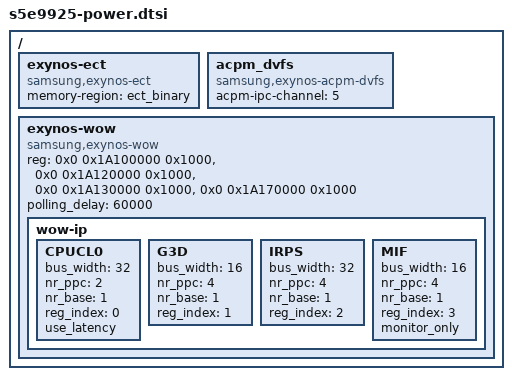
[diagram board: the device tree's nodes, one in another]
/*
 * SAMSUNG EXYNOS2100 SoC DVFS Manager device tree source
 *
 * Copyright (c) 2014 Samsung Electronics Co., Ltd.
 *		http://www.samsung.com
 *
 * SAMSUNG EXYNOS2100 SoC device nodes are listed in this file.
 * EXYNOS based board files can include this file and provide
 * values for board specfic bindings.
 *
 * This program is free software; you can redistribute it and/or modify
 * it under the terms of the GNU General Public License version 2 as
 * published by the Free Software Foundation.
 */

//#include "exynos2100-acpm.dtsi"
#include "s5e9925-dm.dtsi"
#include "s5e9925-devfreq.dtsi"
#include "s5e9925-thermal.dtsi"

/ {
	exynos-ect {
		compatible = "samsung,exynos-ect";
		memory-region = <&ect_binary>;
	};

	acpm_dvfs {
		compatible = "samsung,exynos-acpm-dvfs";
		acpm-ipc-channel = <5>;
	};

	exynos-wow {
		compatible = "samsung,exynos-wow";

		reg = <0x0 0x1A100000 0x1000>,
			<0x0 0x1A120000 0x1000>,
			<0x0 0x1A130000 0x1000>,
			<0x0 0x1A170000 0x1000>;

		polling_delay = <60000>; /* ms */

		wow-ip {
			CPUCL0 {
				bus_width = <32>;
				nr_ppc = <2>;
				nr_base = <1>;
				reg_index = <0>;

				use_latency;
			};
			G3D {
				bus_width = <16>;
				nr_ppc = <4>;
				nr_base = <1>;
				reg_index = <1>;
			};
			IRPS {
				bus_width = <32>;
				nr_ppc = <4>;
				nr_base = <1>;
				reg_index = <2>;
			};
			MIF {
				bus_width = <16>;
				nr_ppc = <4>;
				nr_base = <1>;
				reg_index = <3>;

				monitor_only;
			};
		};
	};
};
